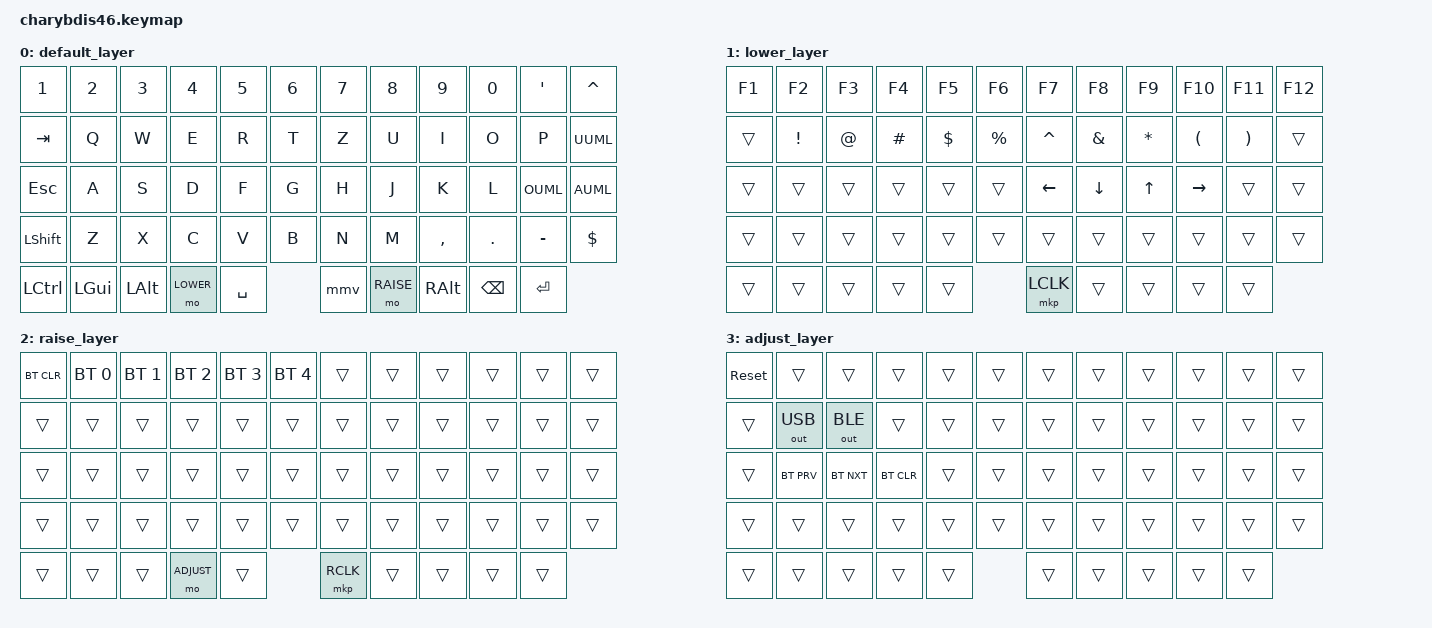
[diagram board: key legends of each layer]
#include <behaviors.dtsi>
#include <dt-bindings/zmk/keys.h>
#include <dt-bindings/zmk/bt.h>
#include <dt-bindings/zmk/outputs.h>
#include <dt-bindings/zmk/mouse.h>

// Layer definitions
#define DEFAULT 0
#define LOWER   1
#define RAISE   2
#define ADJUST  3

// Trackball configuration
&pmw3360 {
    status = "okay";
};

// Behavior customization
/ {
    behaviors {
        // Mouse movement behavior
        mmt: mouse_move_trigger {
            compatible = "zmk,behavior-mouse-move-tap";
            label = "MOUSE_MOVE_TAP";
            #binding-cells = <2>;
            tapping-term-ms = <200>;
            bindings = <&mmv>, <&mkp>;
        };
    };

    keymap {
        compatible = "zmk,keymap";

        default_layer {
            bindings = <
                &kp N1    &kp N2    &kp N3     &kp N4     &kp N5     &kp N6          &kp N7     &kp N8     &kp N9     &kp N0     &kp SQT    &kp CARET
                &kp TAB   &kp Q     &kp W      &kp E      &kp R      &kp T           &kp Z      &kp U      &kp I      &kp O      &kp P      &kp UUML
                &kp ESC   &kp A     &kp S      &kp D      &kp F      &kp G           &kp H      &kp J      &kp K      &kp L      &kp OUML   &kp AUML
                &kp LSHFT &kp Z     &kp X      &kp C      &kp V      &kp B           &kp N      &kp M      &kp COMMA  &kp DOT    &kp MINUS  &kp DOLLAR
                &kp LCTRL &kp LGUI  &kp LALT   &mo LOWER  &kp SPACE                  &mmv       &mo RAISE  &kp RALT   &kp BSPC   &kp RET
            >;

            // Configure trackball for scrolling in default layer
            sensor-bindings = <&scroll_wheel>;
        };

        lower_layer {
            bindings = <
                &kp F1    &kp F2    &kp F3     &kp F4     &kp F5     &kp F6          &kp F7     &kp F8     &kp F9     &kp F10    &kp F11    &kp F12
                &trans    &kp EXCL  &kp AT     &kp HASH   &kp DLLR   &kp PRCNT       &kp CARET  &kp AMPS   &kp STAR   &kp LPAR   &kp RPAR   &trans
                &trans    &trans    &trans     &trans     &trans     &trans          &kp LEFT   &kp DOWN   &kp UP     &kp RIGHT  &trans     &trans
                &trans    &trans    &trans     &trans     &trans     &trans          &trans     &trans     &trans     &trans     &trans     &trans
                &trans    &trans    &trans     &trans     &trans                     &mkp LCLK  &trans     &trans     &trans     &trans
            >;

            // Configure trackball for cursor movement in lower layer
            sensor-bindings = <&mouse_move>;
        };

        raise_layer {
            bindings = <
                &bt BT_CLR &bt BT_SEL 0 &bt BT_SEL 1 &bt BT_SEL 2 &bt BT_SEL 3 &bt BT_SEL 4    &trans     &trans     &trans     &trans     &trans     &trans
                &trans     &trans    &trans     &trans     &trans     &trans          &trans     &trans     &trans     &trans     &trans     &trans
                &trans     &trans    &trans     &trans     &trans     &trans          &trans     &trans     &trans     &trans     &trans     &trans
                &trans     &trans    &trans     &trans     &trans     &trans          &trans     &trans     &trans     &trans     &trans     &trans
                &trans     &trans    &trans     &mo ADJUST &trans                     &mkp RCLK  &trans     &trans     &trans     &trans
            >;

            // Configure trackball for precision movement in raise layer
            sensor-bindings = <&fine_mouse_move>;
        };

        adjust_layer {
            bindings = <
                &sys_reset &trans       &trans       &trans       &trans       &trans          &trans     &trans     &trans     &trans     &trans     &trans
                &trans     &out OUT_USB &out OUT_BLE &trans       &trans       &trans          &trans     &trans     &trans     &trans     &trans     &trans
                &trans     &bt BT_PRV   &bt BT_NXT   &bt BT_CLR   &trans       &trans          &trans     &trans     &trans     &trans     &trans     &trans
                &trans     &trans       &trans       &trans       &trans       &trans          &trans     &trans     &trans     &trans     &trans     &trans
                &trans     &trans       &trans       &trans       &trans                       &trans     &trans     &trans     &trans     &trans
            >;
        };
    };
};

// Trackball movement configuration
/ {
    behaviors {
        scroll_wheel: scroll_wheel {
            compatible = "zmk,behavior-sensor-rotate";
            label = "SCROLL_WHEEL";
            #sensor-binding-cells = <0>;
            bindings = <&msc SCRL_UP>, <&msc SCRL_DOWN>;
        };

        mouse_move: mouse_move {
            compatible = "zmk,behavior-sensor-rotate";
            label = "MOUSE_MOVE";
            #sensor-binding-cells = <0>;
            bindings = <&mmv MOVE_HOR(1500)>, <&mmv MOVE_HOR(-1500)>;
        };

        fine_mouse_move: fine_mouse_move {
            compatible = "zmk,behavior-sensor-rotate";
            label = "FINE_MOUSE_MOVE";
            #sensor-binding-cells = <0>;
            bindings = <&mmv MOVE_HOR(750)>, <&mmv MOVE_HOR(-750)>;
        };
    };
};
